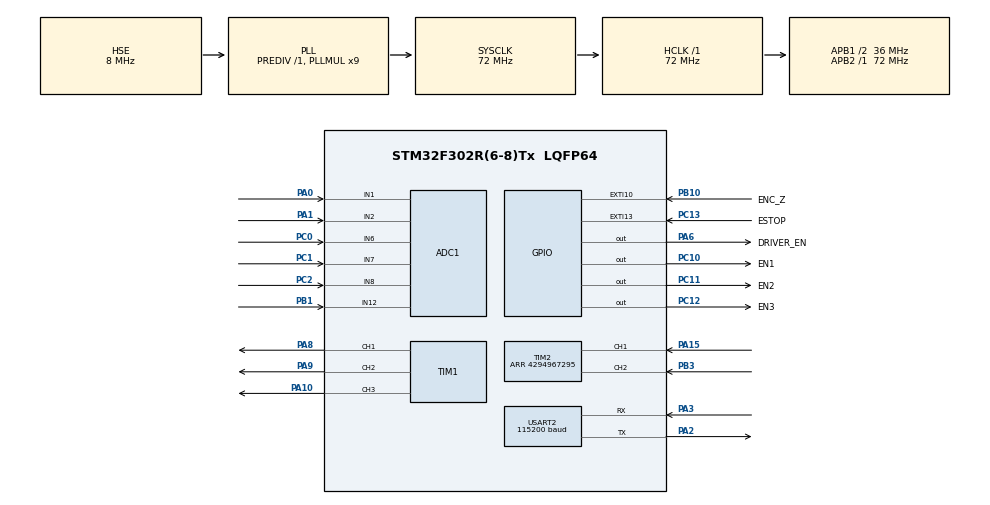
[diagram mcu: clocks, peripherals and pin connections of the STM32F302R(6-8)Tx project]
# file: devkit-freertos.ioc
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ADC1.Channel-9\#ChannelRegularConversion=ADC_CHANNEL_12
ADC1.ClockPrescaler=ADC_CLOCK_SYNC_PCLK_DIV1
ADC1.DataAlign=ADC_DATAALIGN_LEFT
ADC1.EOCSelection=ADC_EOC_SEQ_CONV
ADC1.EnableInjectedConversion=ENABLE
ADC1.EnableRegularConversion=ENABLE
ADC1.ExternalTrigInjecConv=ADC_EXTERNALTRIGINJECCONV_T1_TRGO
ADC1.InjNumberOfConversion=4
ADC1.InjectedChannel-11\#ChannelInjectedConversion=ADC_CHANNEL_12
ADC1.InjectedChannel-6\#ChannelInjectedConversion=ADC_CHANNEL_1
ADC1.InjectedChannel-7\#ChannelInjectedConversion=ADC_CHANNEL_7
ADC1.InjectedChannel-8\#ChannelInjectedConversion=ADC_CHANNEL_6
ADC1.InjectedOffset-11\#ChannelInjectedConversion=0
ADC1.InjectedOffset-6\#ChannelInjectedConversion=0
ADC1.InjectedOffset-7\#ChannelInjectedConversion=0
ADC1.InjectedOffset-8\#ChannelInjectedConversion=0
ADC1.InjectedOffsetNumber-11\#ChannelInjectedConversion=ADC_OFFSET_NONE
ADC1.InjectedOffsetNumber-6\#ChannelInjectedConversion=ADC_OFFSET_NONE
ADC1.InjectedOffsetNumber-7\#ChannelInjectedConversion=ADC_OFFSET_NONE
ADC1.InjectedOffsetNumber-8\#ChannelInjectedConversion=ADC_OFFSET_NONE
ADC1.InjectedRank-11\#ChannelInjectedConversion=4
ADC1.InjectedRank-6\#ChannelInjectedConversion=1
ADC1.InjectedRank-7\#ChannelInjectedConversion=2
ADC1.InjectedRank-8\#ChannelInjectedConversion=3
ADC1.InjectedSamplingTime-11\#ChannelInjectedConversion=ADC_SAMPLETIME_1CYCLE_5
ADC1.InjectedSamplingTime-6\#ChannelInjectedConversion=ADC_SAMPLETIME_1CYCLE_5
ADC1.InjectedSamplingTime-7\#ChannelInjectedConversion=ADC_SAMPLETIME_1CYCLE_5
ADC1.InjectedSamplingTime-8\#ChannelInjectedConversion=ADC_SAMPLETIME_1CYCLE_5
ADC1.InjectedSamplingTimeOPAMP-11\#ChannelInjectedConversion=ADC_SAMPLETIME_61CYCLES_5
ADC1.InjectedSamplingTimeOPAMP-6\#ChannelInjectedConversion=ADC_SAMPLETIME_61CYCLES_5
ADC1.InjectedSamplingTimeOPAMP-7\#ChannelInjectedConversion=ADC_SAMPLETIME_61CYCLES_5
ADC1.InjectedSamplingTimeOPAMP-8\#ChannelInjectedConversion=ADC_SAMPLETIME_61CYCLES_5
ADC1.NbrOfConversion=1
ADC1.NbrOfConversionFlag=1
ADC1.Offset-9\#ChannelRegularConversion=0
ADC1.OffsetNumber-9\#ChannelRegularConversion=ADC_OFFSET_NONE
ADC1.Overrun=ADC_OVR_DATA_PRESERVED
ADC1.QueueInjectedContext=DISABLE
ADC1.Rank-9\#ChannelRegularConversion=1
ADC1.Rank4_Channel=ADC_CHANNEL_12
ADC1.SamplingTime-9\#ChannelRegularConversion=ADC_SAMPLETIME_1CYCLE_5
ADC1.master=1
Mcu.Family=STM32F3
Mcu.Name=STM32F302R(6-8)Tx
Mcu.Package=LQFP64
Mcu.UserConstants=PWM_PERIOD_CYCLES,(ADV_TIM_CLK_MHz*1000000/PWM_FREQUENCY)&0xFFFE;PWM_FREQUENCY,30000;REGULATION_EXECUTION_RATE,1;TIM_CLOCK_DIVIDER,1;ADC_CLK_MHz,72;APB1TIM_FREQ,72000000;HALL_TIM_CLK,72000000;PWM_FREQ_SCALING,1;REP_COUNTER,REGULATION_EXECUTION_RATE*2-1;HTMIN,1;ADV_TIM_CLK_MHz,144;SYSCLK_FREQ,72000000
NVIC.ADC1_IRQn=true\:0\:0\:false\:false\:true\:true\:true\:true
NVIC.EXTI15_10_IRQn=true\:0\:0\:false\:false\:true\:true\:true\:true
NVIC.PriorityGroup=NVIC_PRIORITYGROUP_4
NVIC.TIM1_BRK_TIM15_IRQn=true\:0\:0\:false\:false\:true\:true\:true\:true
NVIC.TIM1_TRG_COM_TIM17_IRQn=true\:0\:0\:false\:false\:true\:true\:true\:true
NVIC.TIM1_UP_TIM16_IRQn=true\:0\:0\:false\:false\:true\:true\:true\:true
NVIC.USART2_IRQn=true\:0\:0\:false\:false\:true\:true\:true\:true
PA0.Mode=IN1-Single-Ended
PA0.Signal=ADC1_IN1
PA1.Mode=IN2-Single-Ended
PA1.Signal=ADC1_IN2
PA10.Signal=S_TIM1_CH3
PA11.Signal=TIM1_BKIN2
PA13.Mode=Serial_Wire
PA13.Signal=SYS_JTMS-SWDIO
PA14.Mode=Serial_Wire
PA14.Signal=SYS_JTCK-SWCLK
PA15.Signal=S_TIM2_CH1_ETR
PA2.Mode=Asynchronous
PA2.Signal=USART2_TX
PA3.Mode=Asynchronous
PA3.Signal=USART2_RX
PA6.GPIO_Label=DRIVER_EN
PA6.Signal=GPIO_Output
PA8.Signal=S_TIM1_CH1
PA9.Signal=S_TIM1_CH2
PB1.Mode=IN12-Single-Ended
PB1.Signal=ADC1_IN12
PB10.GPIO_Label=ENC_Z
PB10.Signal=GPXTI10
PB3.Signal=S_TIM2_CH2
PC0.Signal=ADCx_IN6
PC1.Signal=ADCx_IN7
PC10.GPIO_Label=EN1
PC10.Signal=GPIO_Output
PC11.GPIO_Label=EN2
PC11.Signal=GPIO_Output
PC12.GPIO_Label=EN3
PC12.Signal=GPIO_Output
PC13.GPIO_Label=ESTOP
PC13.GPIO_ModeDefaultEXTI=GPIO_MODE_IT_FALLING
PC13.Signal=GPXTI13
PC2.Signal=ADCx_IN8
PF0-OSC_IN.Mode=HSE-External-Oscillator
PF0-OSC_IN.Signal=RCC_OSC_IN
PF1-OSC_OUT.Mode=HSE-External-Oscillator
PF1-OSC_OUT.Signal=RCC_OSC_OUT
ProjectManager.HeapSize=0x200
ProjectManager.StackSize=0x400
ProjectManager.TargetToolchain=Makefile
RCC.AHBFreq_Value=72000000
RCC.APB1CLKDivider=RCC_HCLK_DIV2
RCC.APB1Freq_Value=36000000
RCC.APB1TimFreq_Value=72000000
RCC.APB2Freq_Value=72000000
RCC.APB2TimFreq_Value=72000000
RCC.CortexFreq_Value=72000000
RCC.HCLKFreq_Value=72000000
RCC.HSE_VALUE=8000000
RCC.HSI_VALUE=8000000
RCC.LSE_VALUE=32768
RCC.PLLMUL=RCC_PLL_MUL9
RCC.PLLSourceVirtual=RCC_PLLSOURCE_HSE
RCC.SYSCLKFreq_VALUE=72000000
RCC.SYSCLKSourceVirtual=RCC_SYSCLKSOURCE_PLLCLK
RCC.TIM1Selection=RCC_TIM1CLK_PLLCLK
RCC.USBFreq_Value=72000000
SH.ADCx_IN6.0=ADC1_IN6,IN6-Single-Ended
SH.ADCx_IN7.0=ADC1_IN7,IN7-Single-Ended
SH.ADCx_IN8.0=ADC1_IN8,IN8-Single-Ended
SH.S_TIM1_CH1.0=TIM1_CH1,PWM Generation1 CH1
SH.S_TIM1_CH2.0=TIM1_CH2,PWM Generation2 CH2
SH.S_TIM1_CH3.0=TIM1_CH3,PWM Generation3 CH3
SH.S_TIM2_CH1_ETR.0=TIM2_CH1,Encoder_Interface
SH.S_TIM2_CH2.0=TIM2_CH2,Encoder_Interface
TIM1.AutomaticOutput=TIM_AUTOMATICOUTPUT_DISABLE
TIM1.Break2Filter=7
TIM1.Break2Polarity=TIM_BREAK2POLARITY_LOW
TIM1.Channel-PWM\ Generation1\ CH1=TIM_CHANNEL_1
TIM1.Channel-PWM\ Generation2\ CH2=TIM_CHANNEL_2
TIM1.Channel-PWM\ Generation3\ CH3=TIM_CHANNEL_3
TIM1.Channel-PWM\ Generation4\ No\ Output=TIM_CHANNEL_4
TIM1.ClockDivision=TIM_CLOCKDIVISION_DIV2
TIM1.CounterMode=TIM_COUNTERMODE_CENTERALIGNED1
TIM1.LockLevel=TIM_LOCKLEVEL_1
TIM1.Period=((PWM_PERIOD_CYCLES) / 2)
TIM1.Prescaler=((TIM_CLOCK_DIVIDER) - 1)
TIM1.Pulse-PWM\ Generation1\ CH1=(PWM_PERIOD_CYCLES) / 4
TIM1.Pulse-PWM\ Generation2\ CH2=(PWM_PERIOD_CYCLES) / 4
TIM1.Pulse-PWM\ Generation3\ CH3=(PWM_PERIOD_CYCLES) / 4
TIM1.Pulse-PWM\ Generation4\ No\ Output=(PWM_PERIOD_CYCLES) / 4
TIM1.RepetitionCounter=REP_COUNTER
TIM1.TIM_MasterOutputTrigger=TIM_TRGO_OC4REF
TIM2.EncoderMode=TIM_ENCODERMODE_TI12
TIM2.Period=4294967295
TIM6.Prescaler=72-1
USART2.BaudRate=115200
USART2.VirtualMode-Asynchronous=VM_ASYNC
VP_TIM1_VS_ClockSourceINT.Mode=Internal
VP_TIM1_VS_no_output4.Mode=PWM Generation4 No Output
VP_TIM6_VS_ClockSourceINT.Mode=Enable_Timer
board=custom

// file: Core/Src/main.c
/* USER CODE BEGIN Header */
/**
  ******************************************************************************
  * @file           : main.c
  * @brief          : Main program body
  ******************************************************************************
  * @attention
  *
  * Copyright (c) 2024 STMicroelectronics.
  * All rights reserved.
  *
  * This software is licensed under terms that can be found in the LICENSE file
  * in the root directory of this software component.
  * If no LICENSE file comes with this software, it is provided AS-IS.
  *
  ******************************************************************************
  */
#include "foc_ctrl.h"
#include "gatedriver.h"
#include "encoder.h"
#include <assert.h>
#include <stdio.h>
#include <math.h>
#include "us_timer.h"
/* USER CODE END Header */
#include "main.h"

/* USER CODE BEGIN Includes */
#include <string.h>
/* USER CODE END Includes */

/* USER CODE BEGIN PTD */
foc_ctrl_t foc_controller;
gatedriver_t gatedrv;
encoder_t encoder;
/* USER CODE END PTD */

/* USER CODE BEGIN PD */
void set_debug_pin(int val) {
  HAL_GPIO_WritePin(USER_GPIO_Port, USER_Pin, val ? GPIO_PIN_SET : GPIO_PIN_RESET);
}
/* USER CODE END PD */

ADC_HandleTypeDef hadc1;

TIM_HandleTypeDef htim1;
TIM_HandleTypeDef htim2;
TIM_HandleTypeDef htim6;

UART_HandleTypeDef huart2;

/* USER CODE BEGIN PV */
int estopped = 0;

void HAL_GPIO_EXTI_Callback(uint16_t pin) {
  if (pin == ENC_Z_Pin)
    encoder_z_pulse_handler(&encoder);
  else if (pin == ESTOP_Pin)
    estopped = 1;
}

#ifdef __GNUC__
#define PUTCHAR_PROTOTYPE int __io_putchar(int ch)
#else
#define PUTCHAR_PROTOTYPE int fputc(int ch, FILE *f)
#endif

PUTCHAR_PROTOTYPE
{
  HAL_UART_Transmit(&huart2, (uint8_t *)&ch, 1, HAL_MAX_DELAY);
  return ch;
}

int _write(int file, char* ptr, int len) {
  int DataIdx;

  for (DataIdx = 0; DataIdx < len; DataIdx++) {
    __io_putchar( *ptr++ );
  }
  return len;
}

/* USER CODE END PV */

void SystemClock_Config(void);
static void MX_GPIO_Init(void);
static void MX_ADC1_Init(void);
static void MX_TIM1_Init(void);
static void MX_USART2_UART_Init(void);
static void MX_TIM2_Init(void);
static void MX_TIM6_Init(void);

/* USER CODE BEGIN 0 */
#define ADC_MAX_VALUE              (0xFFFF)
// VBUS is read through a voltage divider between a 169k and a 9.31k resistor
//                 (Scale ADC sample to voltage)     (voltage divider)
#define SAMPLE_TO_VOLTAGE (3.3f / ADC_MAX_VALUE)
#define SAMPLE_TO_NORMALIZED (1.0f / ADC_MAX_VALUE)
#define SAMPLE_TO_VBUS (SAMPLE_TO_VOLTAGE / (9.31f / (169.0f + 9.31f)))

float vbus_read() {
  // // bus voltage is read from ADC1 Channel 2
  // HAL_ADC_Start(&hadc1);

  // HAL_ADC_PollForConversion(&hadc1, HAL_MAX_DELAY);
  // int dr = HAL_ADC_GetValue(&hadc1);

  // return dr * SAMPLE_TO_VBUS;
  return 11.2;
}

float get_user_phase() {
  return hadc1.Instance->JDR4 * SAMPLE_TO_NORMALIZED * 2 * M_PI;
}

void enable_driver() {
  HAL_GPIO_WritePin(DRIVER_EN_GPIO_Port, DRIVER_EN_Pin, GPIO_PIN_SET);
}

void enable_driver_phases() {
  HAL_GPIO_WritePin(EN1_GPIO_Port, EN1_Pin, GPIO_PIN_SET);
  HAL_GPIO_WritePin(EN2_GPIO_Port, EN2_Pin, GPIO_PIN_SET);
  HAL_GPIO_WritePin(EN3_GPIO_Port, EN3_Pin, GPIO_PIN_SET);
}

void disable_driver() {
  HAL_GPIO_WritePin(DRIVER_EN_GPIO_Port, DRIVER_EN_Pin, GPIO_PIN_RESET);
}

void disable_driver_phases() {
  HAL_GPIO_WritePin(EN1_GPIO_Port, EN1_Pin, GPIO_PIN_RESET);
  HAL_GPIO_WritePin(EN2_GPIO_Port, EN2_Pin, GPIO_PIN_RESET);
  HAL_GPIO_WritePin(EN3_GPIO_Port, EN3_Pin, GPIO_PIN_RESET);
}

int estop_check() {
  return estopped;
}

void estop_handler() {
  printf("Estop pressed! Reset board to restart motor\r\n");
  gatedrv_write_pwm(&gatedrv, (float[3]) { 0.0, 0.0, 0.0 });
  disable_driver();
  disable_driver_phases();
  Error_Handler();
}

/* USER CODE END 0 */

int main(void)
{

  /* MCU Configuration--------------------------------------------------------*/

  /* Reset of all peripherals, Initializes the Flash interface and the Systick. */
  HAL_Init();

  /* Configure the system clock */
  SystemClock_Config();

  /* Initialize all configured peripherals */
  MX_GPIO_Init();
  MX_ADC1_Init();
  MX_TIM1_Init();
  MX_USART2_UART_Init();
  MX_TIM2_Init();
  MX_TIM6_Init();
  /* USER CODE BEGIN 2 */
  float duty_cycles[3];
  float phase_currents[3];

  // init hardware
  us_timer_init(&htim6);
  foc_ctrl_init(&foc_controller);
  gatedrv_init(&gatedrv, &htim1, &hadc1);
  encoder_init(&encoder, &htim2);

  // drive enable pins high
  // disable_driver();
  // disable_driver_phases();
  enable_driver();
  enable_driver_phases();
  int i = 0;

  float vbus_voltage;
  float position;
  float velocity;

  set_debug_pin(0);
  /* USER CODE END 2 */

  /* Infinite loop */
  /* USER CODE BEGIN WHILE */
  while (1)
  {
    if (estop_check())
      estop_handler();

    // // Read vbus
    // vbus_voltage = vbus_read();
    // foc_ctrl_update_v_ref(&foc_controller, vbus_voltage);

    // // // Get ref current
    // float ref_current = 0.2; // A
    // foc_ctrl_update_ref_current(&foc_controller, ref_current);

    // // Wait for injected adc to be done
    // HAL_ADCEx_InjectedPollForConversion(&hadc1, HAL_MAX_DELAY);

    // gatedrv_get_phase_currents(&gatedrv, phase_currents);

    // // Get encoder velocity
    // velocity = encoder_calculate_velocity(&encoder, us_timer_get() / 1000000.0);
    // position = encoder_read_angle(&encoder);
    // foc_ctrl_update_encoder(&foc_controller, velocity, position);

		foc_ctrl_run(&foc_controller, phase_currents, duty_cycles);

    gatedrv_write_pwm(&gatedrv, duty_cycles);

    // print very infreqently
    // if (i++ % 400 == 0) {
    //   printf("V Bus reading: %6.3f ", vbus_voltage);
    //   printf("Rotor Angle: %6.3f ", position);
    //   printf("Rotor Speed: %8.3f ", velocity);
    //   printf("Reference Current: %4.1f ", ref_current);
    //   printf("Read phase currents: %6.3f %6.3f %6.3f ", phase_currents[0], phase_currents[1], phase_currents[2]);
    //   printf("Duty Cycles: %6.3f %6.3f %6.3f ", duty_cycles[0], duty_cycles[1], duty_cycles[2]);
    //   printf("Mode: %s", foc_controller.mode == FOC_CLOSED_LOOP ? "Closed" : "Open");
    //   printf("\r");
    // }
    /* USER CODE END WHILE */

  }
}

void SystemClock_Config(void)
{
  RCC_OscInitTypeDef RCC_OscInitStruct = {0};
  RCC_ClkInitTypeDef RCC_ClkInitStruct = {0};
  RCC_PeriphCLKInitTypeDef PeriphClkInit = {0};

  /** Initializes the RCC Oscillators according to the specified parameters
  * in the RCC_OscInitTypeDef structure.
  */
  RCC_OscInitStruct.OscillatorType = RCC_OSCILLATORTYPE_HSE;
  RCC_OscInitStruct.HSEState = RCC_HSE_ON;
  RCC_OscInitStruct.HSEPredivValue = RCC_HSE_PREDIV_DIV1;
  RCC_OscInitStruct.HSIState = RCC_HSI_ON;
  RCC_OscInitStruct.PLL.PLLState = RCC_PLL_ON;
  RCC_OscInitStruct.PLL.PLLSource = RCC_PLLSOURCE_HSE;
  RCC_OscInitStruct.PLL.PLLMUL = RCC_PLL_MUL9;
  if (HAL_RCC_OscConfig(&RCC_OscInitStruct) != HAL_OK)
  {
    Error_Handler();
  }

  /** Initializes the CPU, AHB and APB buses clocks
  */
  RCC_ClkInitStruct.ClockType = RCC_CLOCKTYPE_HCLK|RCC_CLOCKTYPE_SYSCLK
                              |RCC_CLOCKTYPE_PCLK1|RCC_CLOCKTYPE_PCLK2;
  RCC_ClkInitStruct.SYSCLKSource = RCC_SYSCLKSOURCE_PLLCLK;
  RCC_ClkInitStruct.AHBCLKDivider = RCC_SYSCLK_DIV1;
  RCC_ClkInitStruct.APB1CLKDivider = RCC_HCLK_DIV2;
  RCC_ClkInitStruct.APB2CLKDivider = RCC_HCLK_DIV1;

  if (HAL_RCC_ClockConfig(&RCC_ClkInitStruct, FLASH_LATENCY_2) != HAL_OK)
  {
    Error_Handler();
  }
  PeriphClkInit.PeriphClockSelection = RCC_PERIPHCLK_TIM1;
  PeriphClkInit.Tim1ClockSelection = RCC_TIM1CLK_PLLCLK;
  if (HAL_RCCEx_PeriphCLKConfig(&PeriphClkInit) != HAL_OK)
  {
    Error_Handler();
  }
}

static void MX_ADC1_Init(void)
{

  ADC_InjectionConfTypeDef sConfigInjected = {0};
  ADC_ChannelConfTypeDef sConfig = {0};

  /** Common config
  */
  hadc1.Instance = ADC1;
  hadc1.Init.ClockPrescaler = ADC_CLOCK_SYNC_PCLK_DIV1;
  hadc1.Init.Resolution = ADC_RESOLUTION_12B;
  hadc1.Init.ScanConvMode = ADC_SCAN_ENABLE;
  hadc1.Init.ContinuousConvMode = DISABLE;
  hadc1.Init.DiscontinuousConvMode = DISABLE;
  hadc1.Init.ExternalTrigConvEdge = ADC_EXTERNALTRIGCONVEDGE_NONE;
  hadc1.Init.ExternalTrigConv = ADC_SOFTWARE_START;
  hadc1.Init.DataAlign = ADC_DATAALIGN_LEFT;
  hadc1.Init.NbrOfConversion = 1;
  hadc1.Init.DMAContinuousRequests = DISABLE;
  hadc1.Init.EOCSelection = ADC_EOC_SEQ_CONV;
  hadc1.Init.LowPowerAutoWait = DISABLE;
  hadc1.Init.Overrun = ADC_OVR_DATA_PRESERVED;
  if (HAL_ADC_Init(&hadc1) != HAL_OK)
  {
    Error_Handler();
  }

  /** Configure Injected Channel
  */
  sConfigInjected.InjectedChannel = ADC_CHANNEL_1;
  sConfigInjected.InjectedRank = ADC_INJECTED_RANK_1;
  sConfigInjected.InjectedSingleDiff = ADC_SINGLE_ENDED;
  sConfigInjected.InjectedNbrOfConversion = 3;
  sConfigInjected.InjectedSamplingTime = ADC_SAMPLETIME_1CYCLE_5;
  sConfigInjected.ExternalTrigInjecConvEdge = ADC_EXTERNALTRIGINJECCONV_EDGE_RISING;
  sConfigInjected.ExternalTrigInjecConv = ADC_EXTERNALTRIGINJECCONV_T1_TRGO;
  sConfigInjected.AutoInjectedConv = DISABLE;
  sConfigInjected.InjectedDiscontinuousConvMode = DISABLE;
  sConfigInjected.QueueInjectedContext = DISABLE;
  sConfigInjected.InjectedOffset = 0;
  sConfigInjected.InjectedOffsetNumber = ADC_OFFSET_NONE;
  if (HAL_ADCEx_InjectedConfigChannel(&hadc1, &sConfigInjected) != HAL_OK)
  {
    Error_Handler();
  }

  /** Configure Injected Channel
  */
  sConfigInjected.InjectedChannel = ADC_CHANNEL_7;
  sConfigInjected.InjectedRank = ADC_INJECTED_RANK_2;
  if (HAL_ADCEx_InjectedConfigChannel(&hadc1, &sConfigInjected) != HAL_OK)
  {
    Error_Handler();
  }

  /** Configure Injected Channel
  */
  sConfigInjected.InjectedChannel = ADC_CHANNEL_6;
  sConfigInjected.InjectedRank = ADC_INJECTED_RANK_3;
  if (HAL_ADCEx_InjectedConfigChannel(&hadc1, &sConfigInjected) != HAL_OK)
  {
    Error_Handler();
  }

  /** Configure Regular Channel
  */
  sConfig.Channel = ADC_CHANNEL_1;
  sConfig.Rank = ADC_REGULAR_RANK_1;
  sConfig.SingleDiff = ADC_SINGLE_ENDED;
  sConfig.SamplingTime = ADC_SAMPLETIME_1CYCLE_5;
  sConfig.OffsetNumber = ADC_OFFSET_NONE;
  sConfig.Offset = 0;
  if (HAL_ADC_ConfigChannel(&hadc1, &sConfig) != HAL_OK)
  {
    Error_Handler();
  }

}

static void MX_TIM1_Init(void)
{

  TIM_ClockConfigTypeDef sClockSourceConfig = {0};
  TIM_MasterConfigTypeDef sMasterConfig = {0};
  TIM_OC_InitTypeDef sConfigOC = {0};
  TIM_BreakDeadTimeConfigTypeDef sBreakDeadTimeConfig = {0};

  htim1.Instance = TIM1;
  htim1.Init.Prescaler = ((TIM_CLOCK_DIVIDER) - 1);
  htim1.Init.CounterMode = TIM_COUNTERMODE_CENTERALIGNED1;
  htim1.Init.Period = ((PWM_PERIOD_CYCLES) / 2);
  htim1.Init.ClockDivision = TIM_CLOCKDIVISION_DIV2;
  htim1.Init.RepetitionCounter = REP_COUNTER;
  htim1.Init.AutoReloadPreload = TIM_AUTORELOAD_PRELOAD_DISABLE;
  if (HAL_TIM_Base_Init(&htim1) != HAL_OK)
  {
    Error_Handler();
  }
  sClockSourceConfig.ClockSource = TIM_CLOCKSOURCE_INTERNAL;
  if (HAL_TIM_ConfigClockSource(&htim1, &sClockSourceConfig) != HAL_OK)
  {
    Error_Handler();
  }
  if (HAL_TIM_PWM_Init(&htim1) != HAL_OK)
  {
    Error_Handler();
  }
  sMasterConfig.MasterOutputTrigger = TIM_TRGO_OC4REF;
  sMasterConfig.MasterOutputTrigger2 = TIM_TRGO2_RESET;
  sMasterConfig.MasterSlaveMode = TIM_MASTERSLAVEMODE_DISABLE;
  if (HAL_TIMEx_MasterConfigSynchronization(&htim1, &sMasterConfig) != HAL_OK)
  {
    Error_Handler();
  }
  sConfigOC.OCMode = TIM_OCMODE_PWM1;
  sConfigOC.Pulse = (PWM_PERIOD_CYCLES) / 4;
  sConfigOC.OCPolarity = TIM_OCPOLARITY_HIGH;
  sConfigOC.OCNPolarity = TIM_OCNPOLARITY_HIGH;
  sConfigOC.OCFastMode = TIM_OCFAST_DISABLE;
  sConfigOC.OCIdleState = TIM_OCIDLESTATE_RESET;
  sConfigOC.OCNIdleState = TIM_OCNIDLESTATE_RESET;
  if (HAL_TIM_PWM_ConfigChannel(&htim1, &sConfigOC, TIM_CHANNEL_1) != HAL_OK)
  {
    Error_Handler();
  }
  if (HAL_TIM_PWM_ConfigChannel(&htim1, &sConfigOC, TIM_CHANNEL_2) != HAL_OK)
  {
    Error_Handler();
  }
  if (HAL_TIM_PWM_ConfigChannel(&htim1, &sConfigOC, TIM_CHANNEL_3) != HAL_OK)
  {
    Error_Handler();
  }
  if (HAL_TIM_PWM_ConfigChannel(&htim1, &sConfigOC, TIM_CHANNEL_4) != HAL_OK)
  {
    Error_Handler();
  }
  sBreakDeadTimeConfig.OffStateRunMode = TIM_OSSR_DISABLE;
  sBreakDeadTimeConfig.OffStateIDLEMode = TIM_OSSI_DISABLE;
  sBreakDeadTimeConfig.LockLevel = TIM_LOCKLEVEL_1;
  sBreakDeadTimeConfig.DeadTime = 0;
  sBreakDeadTimeConfig.BreakState = TIM_BREAK_DISABLE;
  sBreakDeadTimeConfig.BreakPolarity = TIM_BREAKPOLARITY_HIGH;
  sBreakDeadTimeConfig.BreakFilter = 0;
  sBreakDeadTimeConfig.Break2State = TIM_BREAK2_DISABLE;
  sBreakDeadTimeConfig.Break2Polarity = TIM_BREAK2POLARITY_LOW;
  sBreakDeadTimeConfig.Break2Filter = 7;
  sBreakDeadTimeConfig.AutomaticOutput = TIM_AUTOMATICOUTPUT_DISABLE;
  if (HAL_TIMEx_ConfigBreakDeadTime(&htim1, &sBreakDeadTimeConfig) != HAL_OK)
  {
    Error_Handler();
  }
  HAL_TIM_MspPostInit(&htim1);

}

static void MX_TIM2_Init(void)
{

  TIM_Encoder_InitTypeDef sConfig = {0};
  TIM_MasterConfigTypeDef sMasterConfig = {0};

  htim2.Instance = TIM2;
  htim2.Init.Prescaler = 0;
  htim2.Init.CounterMode = TIM_COUNTERMODE_UP;
  htim2.Init.Period = 4294967295;
  htim2.Init.ClockDivision = TIM_CLOCKDIVISION_DIV1;
  htim2.Init.AutoReloadPreload = TIM_AUTORELOAD_PRELOAD_DISABLE;
  sConfig.EncoderMode = TIM_ENCODERMODE_TI12;
  sConfig.IC1Polarity = TIM_ICPOLARITY_RISING;
  sConfig.IC1Selection = TIM_ICSELECTION_DIRECTTI;
  sConfig.IC1Prescaler = TIM_ICPSC_DIV1;
  sConfig.IC1Filter = 0;
  sConfig.IC2Polarity = TIM_ICPOLARITY_RISING;
  sConfig.IC2Selection = TIM_ICSELECTION_DIRECTTI;
  sConfig.IC2Prescaler = TIM_ICPSC_DIV1;
  sConfig.IC2Filter = 0;
  if (HAL_TIM_Encoder_Init(&htim2, &sConfig) != HAL_OK)
  {
    Error_Handler();
  }
  sMasterConfig.MasterOutputTrigger = TIM_TRGO_RESET;
  sMasterConfig.MasterSlaveMode = TIM_MASTERSLAVEMODE_DISABLE;
  if (HAL_TIMEx_MasterConfigSynchronization(&htim2, &sMasterConfig) != HAL_OK)
  {
    Error_Handler();
  }

}

static void MX_TIM6_Init(void)
{

  TIM_MasterConfigTypeDef sMasterConfig = {0};

  htim6.Instance = TIM6;
  htim6.Init.Prescaler = 72-1;
  htim6.Init.CounterMode = TIM_COUNTERMODE_UP;
  htim6.Init.Period = 65535;
  htim6.Init.AutoReloadPreload = TIM_AUTORELOAD_PRELOAD_DISABLE;
  if (HAL_TIM_Base_Init(&htim6) != HAL_OK)
  {
    Error_Handler();
  }
  sMasterConfig.MasterOutputTrigger = TIM_TRGO_RESET;
  sMasterConfig.MasterSlaveMode = TIM_MASTERSLAVEMODE_DISABLE;
  if (HAL_TIMEx_MasterConfigSynchronization(&htim6, &sMasterConfig) != HAL_OK)
  {
    Error_Handler();
  }

}

static void MX_USART2_UART_Init(void)
{

  huart2.Instance = USART2;
  huart2.Init.BaudRate = 115200;
  huart2.Init.WordLength = UART_WORDLENGTH_8B;
  huart2.Init.StopBits = UART_STOPBITS_1;
  huart2.Init.Parity = UART_PARITY_NONE;
  huart2.Init.Mode = UART_MODE_TX_RX;
  huart2.Init.HwFlowCtl = UART_HWCONTROL_NONE;
  huart2.Init.OverSampling = UART_OVERSAMPLING_16;
  huart2.Init.OneBitSampling = UART_ONE_BIT_SAMPLE_DISABLE;
  huart2.AdvancedInit.AdvFeatureInit = UART_ADVFEATURE_NO_INIT;
  if (HAL_UART_Init(&huart2) != HAL_OK)
  {
    Error_Handler();
  }

}

static void MX_GPIO_Init(void)
{
  GPIO_InitTypeDef GPIO_InitStruct = {0};

  /* GPIO Ports Clock Enable */
  __HAL_RCC_GPIOC_CLK_ENABLE();
  __HAL_RCC_GPIOF_CLK_ENABLE();
  __HAL_RCC_GPIOA_CLK_ENABLE();
  __HAL_RCC_GPIOB_CLK_ENABLE();

  /*Configure GPIO pin Output Level */
  HAL_GPIO_WritePin(DRIVER_EN_GPIO_Port, DRIVER_EN_Pin, GPIO_PIN_RESET);

  /*Configure GPIO pin Output Level */
  HAL_GPIO_WritePin(USER_GPIO_Port, USER_Pin, GPIO_PIN_RESET);

  /*Configure GPIO pin Output Level */
  HAL_GPIO_WritePin(GPIOC, EN1_Pin|EN2_Pin|EN3_Pin, GPIO_PIN_RESET);

  /*Configure GPIO pin : ESTOP_Pin */
  GPIO_InitStruct.Pin = ESTOP_Pin;
  GPIO_InitStruct.Mode = GPIO_MODE_IT_FALLING;
  GPIO_InitStruct.Pull = GPIO_NOPULL;
  HAL_GPIO_Init(ESTOP_GPIO_Port, &GPIO_InitStruct);

  /*Configure GPIO pin : DRIVER_EN_Pin */
  GPIO_InitStruct.Pin = DRIVER_EN_Pin;
  GPIO_InitStruct.Mode = GPIO_MODE_OUTPUT_PP;
  GPIO_InitStruct.Pull = GPIO_NOPULL;
  GPIO_InitStruct.Speed = GPIO_SPEED_FREQ_LOW;
  HAL_GPIO_Init(DRIVER_EN_GPIO_Port, &GPIO_InitStruct);

  /*Configure GPIO pin : USER_Pin */
  GPIO_InitStruct.Pin = USER_Pin;
  GPIO_InitStruct.Mode = GPIO_MODE_OUTPUT_PP;
  GPIO_InitStruct.Pull = GPIO_NOPULL;
  GPIO_InitStruct.Speed = GPIO_SPEED_FREQ_LOW;
  HAL_GPIO_Init(USER_GPIO_Port, &GPIO_InitStruct);

  /*Configure GPIO pin : ENC_Z_Pin */
  GPIO_InitStruct.Pin = ENC_Z_Pin;
  GPIO_InitStruct.Mode = GPIO_MODE_IT_RISING;
  GPIO_InitStruct.Pull = GPIO_NOPULL;
  HAL_GPIO_Init(ENC_Z_GPIO_Port, &GPIO_InitStruct);

  /*Configure GPIO pins : EN1_Pin EN2_Pin EN3_Pin */
  GPIO_InitStruct.Pin = EN1_Pin|EN2_Pin|EN3_Pin;
  GPIO_InitStruct.Mode = GPIO_MODE_OUTPUT_PP;
  GPIO_InitStruct.Pull = GPIO_NOPULL;
  GPIO_InitStruct.Speed = GPIO_SPEED_FREQ_LOW;
  HAL_GPIO_Init(GPIOC, &GPIO_InitStruct);

  /* EXTI interrupt init*/
  HAL_NVIC_SetPriority(EXTI15_10_IRQn, 0, 0);
  HAL_NVIC_EnableIRQ(EXTI15_10_IRQn);

}

void Error_Handler(void)
{
  __disable_irq();
  while (1)
  {
  }
}
